# CH32X035 register map
Vendor: WCH Ltd.; File version: 1.0
Registers are 32-bit, read-write, reset 0x0 unless marked. A register's access mark holds for its fields unless they carry their own. Offsets are from the block's base; [hi:lo] are bit positions; {n}, {i} and the like mark numbered series.

## DBG — Debug support
Base 0xE000D000
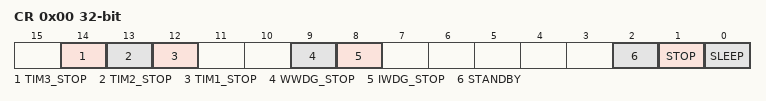
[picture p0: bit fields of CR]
0x00 CR — DBGMCU_CR
  [14] TIM3_STOP, [13] TIM2_STOP, [12] TIM1_STOP, [9] WWDG_STOP, [8] IWDG_STOP, [2] STANDBY, [1] STOP, [0] SLEEP

## FLASH
Base 0x40022000
0x00 ACTLR — Flash ACTL register
  [1:0] LATENCY
0x04 KEYR wo — Flash key register
  [31:0] KEYR — FPEC key
0x08 OBKEYR wo — Flash option key register
  [31:0] OPTKEY — Option byte key
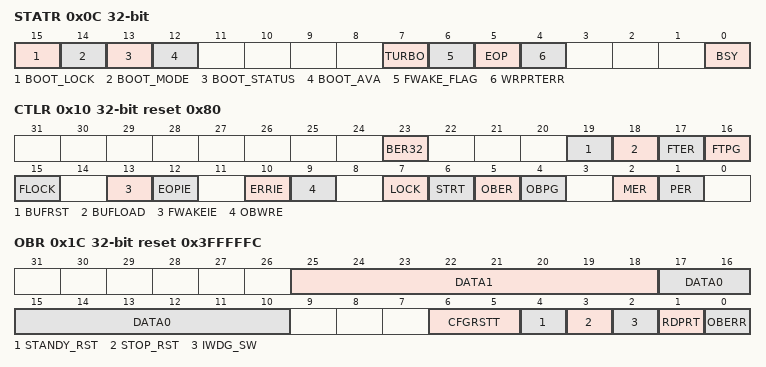
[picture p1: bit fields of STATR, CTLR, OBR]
0x0C STATR access per field — Status register
  [15] BOOT_LOCK rw
  [14] BOOT_MODE rw
  [13] BOOT_STATUS ro
  [12] BOOT_AVA ro
  [7] TURBO ro — TURBO mode start
  [6] FWAKE_FLAG rw — FWAKE_FLAG mode start
  [5] EOP rw — End of operation
  [4] WRPRTERR rw — Write protection error
  [0] BSY ro — Busy
0x10 CTLR reset 0x80 — Control register
  [23] BER32
  [19] BUFRST
  [18] BUFLOAD
  [17] FTER — Fast erase
  [16] FTPG — Fast programming
  [15] FLOCK — Fast programmable lock
  [13] FWAKEIE — Wakeup enable
  [12] EOPIE — End of operation interrupt enable
  [10] ERRIE — Error interrupt enable
  [9] OBWRE — Option bytes write enable
  [7] LOCK
  [6] STRT — Start
  [5] OBER — Option byte erase
  [4] OBPG — Option byte programming
  [2] MER — Mass Erase
  [1] PER — Page Erase
0x14 ADDR wo — Flash address register
  [31:0] FAR — Flash Address
0x1C OBR ro reset 0x3FFFFFC — Option byte register
  [25:18] DATA1
  [17:10] DATA0
  [6:5] CFGRSTT — Config reset delay time
  [4] STANDY_RST
  [3] STOP_RST
  [2] IWDG_SW
  [1] RDPRT — Read protection
  [0] OBERR — Option byte error
0x20 WPR ro reset 0xFFFFFFFF — Write protection register
  [31:0] WRP — Write protect
0x24 MODEKEYR wo — Mode select register
  [31:0] MODEKEYR — Mode select
0x28 BOOT_MODEKEYP wo — BOOT Mode select register
  [31:0] MODEKEYR — Mode select

## PFIC — Programmable Fast Interrupt Controller
Base 0xE000E000
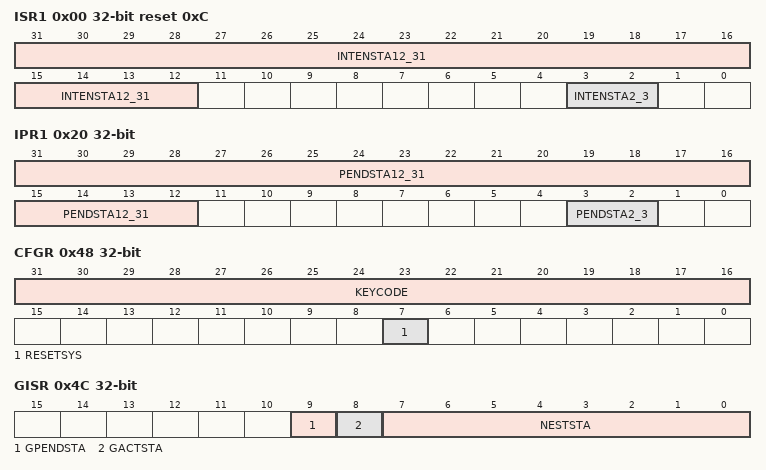
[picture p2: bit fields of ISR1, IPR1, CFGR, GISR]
0x00 ISR1 ro reset 0xC — Interrupt Status Register
  [31:12] INTENSTA12_31 — Interrupt ID Status
  [3:2] INTENSTA2_3 — Interrupt ID Status
0x04 ISR2 ro — Interrupt Status Register
  [31:0] INTENSTA — Interrupt ID Status
0x08 ISR3 ro — Interrupt Status Register
  [31:0] INTENSTA — Interrupt ID Status
0x0C ISR4 ro — Interrupt Status Register
  [7:0] INTENSTA — Interrupt ID Status
0x20 IPR1 ro — Interrupt Pending Register
  [31:12] PENDSTA12_31 — PENDSTA
  [3:2] PENDSTA2_3 — PENDSTA
0x24 IPR2 ro — Interrupt Pending Register
  [31:0] PENDSTA
0x28 IPR3 ro — Interrupt Pending Register
  [31:0] PENDSTA
0x2C IPR4 ro — Interrupt Pending Register
  [7:0] PENDSTA
0x40 ITHRESDR — Interrupt Priority Register
  [7:0] THRESHOLD
0x48 CFGR wo — Interrupt Config Register
  [31:16] KEYCODE, [7] RESETSYS
0x4C GISR ro — Interrupt Global Register
  [9] GPENDSTA, [8] GACTSTA, [7:0] NESTSTA
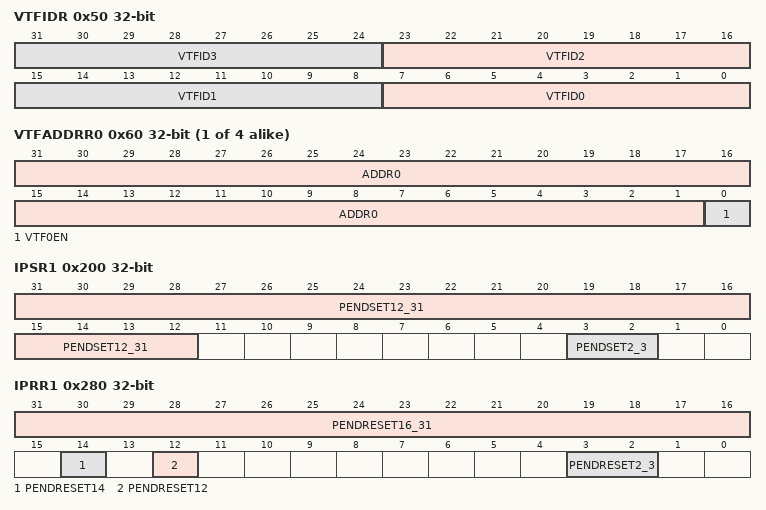
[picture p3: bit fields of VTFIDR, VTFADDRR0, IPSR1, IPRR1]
0x50 VTFIDR — ID Config Register
  [8n+7:8n] VTFID{n} (n=0..3)
{0x60+4i} VTFADDRR{i} (i=0..3) — Interrupt {i} address Register
  [31:1] ADDR{i}, [0] VTF{i}EN
0x100 IENR1 wo — Interrupt Setting Register
  [31:12] INTEN
0x104 IENR2 wo — Interrupt Setting Register
  [31:0] INTEN
0x108 IENR3 wo — Interrupt Setting Register
  [31:0] INTEN
0x10C IENR4 wo — Interrupt Setting Register
  [7:0] INTEN
0x180 IRER1 wo — Interrupt Clear Register
  [31:12] INTRSET
0x184 IRER2 wo — Interrupt Clear Register
  [31:0] INTRSET
0x188 IRER3 wo — Interrupt Clear Register
  [31:0] INTRSET
0x18C IRER4 wo — Interrupt Clear Register
  [7:0] INTRSET
0x200 IPSR1 wo — Interrupt Pending Register
  [31:12] PENDSET12_31 — PENDSET
  [3:2] PENDSET2_3 — PENDSET
0x204 IPSR2 wo — Interrupt Pending Register
  [31:0] PENDSET
0x208 IPSR3 wo — Interrupt Pending Register
  [31:0] PENDSET
0x20C IPSR4 wo — Interrupt Pending Register
  [7:0] PENDSET
0x280 IPRR1 wo — Interrupt Pending Clear Register
  [31:16] PENDRESET16_31 — PENDRESET
  [14] PENDRESET14 — PENDRESET
  [12] PENDRESET12 — PENDRESET
  [3:2] PENDRESET2_3 — PENDRESET
0x284 IPRR2 wo — Interrupt Pending Clear Register
  [31:0] PENDRESET
0x288 IPRR3 wo — Interrupt Pending Clear Register
  [31:0] PENDRESET
0x28C IPRR4 wo — Interrupt Pending Clear Register
  [7:0] PENDRESET
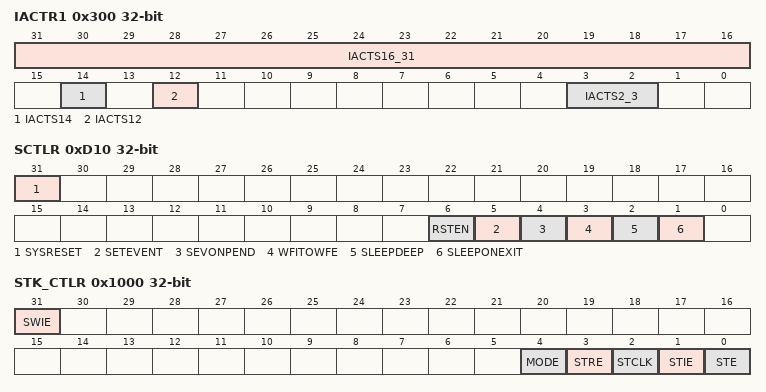
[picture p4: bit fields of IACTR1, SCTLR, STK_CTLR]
0x300 IACTR1 wo — Interrupt ACTIVE Register
  [31:16] IACTS16_31 — IACTS
  [14] IACTS14 — IACTS
  [12] IACTS12 — IACTS
  [3:2] IACTS2_3 — IACTS
0x304 IACTR2 wo — Interrupt ACTIVE Register
  [31:0] IACTS
0x308 IACTR3 wo — Interrupt ACTIVE Register
  [31:0] IACTS
0x30C IACTR4 wo — Interrupt ACTIVE Register
  [7:0] IACTS
{0x400+i} IPRIOR{i} 8-bit (i=0..63) — Interrupt Priority Register
0xD10 SCTLR — System Control Register
  [31] SYSRESET, [6] RSTEN, [5] SETEVENT, [4] SEVONPEND, [3] WFITOWFE, [2] SLEEPDEEP, [1] SLEEPONEXIT
0x1000 STK_CTLR — System counter control register
  [31] SWIE — System software triggered interrupts enable
  [4] MODE — System Mode
  [3] STRE — System reload register
  [2] STCLK — System selects the clock source
  [1] STIE — System counter interrupt enable
  [0] STE — System counter enable
0x1004 STK_SR — System START
  [0] CNTIF
0x1008 STK_CNTL — System counter low register
0x100C STK_CNTH — System counter high register
0x1010 STK_CMPLR — System compare low register
  [31:0] CMPL
0x1014 STK_CMPHR — System compare high register
  [31:0] CMPH
